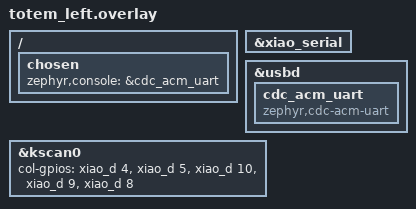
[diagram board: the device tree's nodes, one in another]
/*
 * Copyright (c) 2022 The ZMK Contributors
 *
 * SPDX-License-Identifier: MIT
 */

#include "totem.dtsi"

/* Re-enable hardware UART0 for wired split (disabled by the xiao_rp2040//zmk variant) */
&xiao_serial { status = "okay"; };

&usbd {
    cdc_acm_uart: cdc_acm_uart {
        compatible = "zephyr,cdc-acm-uart";
    };
};

/ {
    chosen {
        zephyr,console = &cdc_acm_uart;
    };
};

&kscan0 {
    col-gpios
        = <&xiao_d 4 GPIO_ACTIVE_HIGH>
        , <&xiao_d 5 GPIO_ACTIVE_HIGH>
        , <&xiao_d 10 GPIO_ACTIVE_HIGH>
        , <&xiao_d 9 GPIO_ACTIVE_HIGH>
        , <&xiao_d 8 GPIO_ACTIVE_HIGH>
        ;
};
